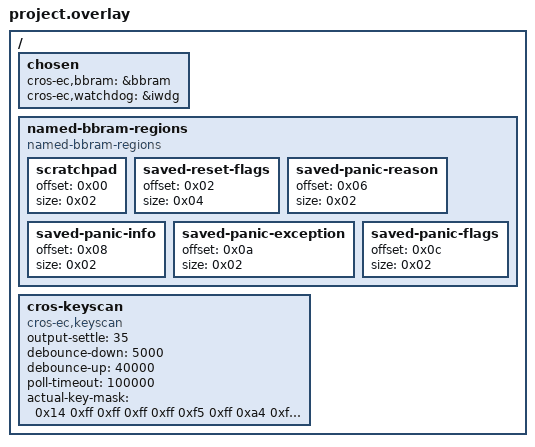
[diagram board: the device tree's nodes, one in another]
/* project dts */
#include "../gpio.dtsi"

/ {
	chosen {
		cros-ec,bbram = &bbram;
		cros-ec,watchdog = &iwdg;
		//cros-ec,raw-kb = &cros_kb_raw;
	};

	/* this field maybe is not correct but add this to build pass */
	named-bbram-regions {
		compatible = "named-bbram-regions";

		scratchpad {
			offset = <0x00>;
			size = <0x02>;
		};
		saved-reset-flags {
			offset = <0x02>;
			size = <0x04>;
		};
		saved-panic-reason {
			offset = <0x06>;
			size = <0x02>;
		};
		saved-panic-info {
			offset = <0x08>;
			size = <0x02>;
		};
		saved-panic-exception {
			offset = <0x0a>;
			size = <0x02>;
		};
		saved-panic-flags {
			offset = <0x0c>;
			size = <0x02>;
		};
	};

	cros-keyscan {
		compatible = "cros-ec,keyscan";

		output-settle = <35>;
		debounce-down = <5000>;
		debounce-up = <40000>;
		poll-timeout = <100000>;

		actual-key-mask = <
			0x14	/* C0 */
			0xff	/* C1 */
			0xff	/* C2 */
			0xff	/* C3 */
			0xff	/* C4 */
			0xf5	/* C5 */
			0xff	/* C6 */
			0xa4	/* C7 */
			0xff	/* C8 */
			0xfe	/* C9 */
			0x55	/* C10 */
			0xfa	/* C11 */
			0xca	/* C12 */
			>;
		status = "okay";
	};
};
